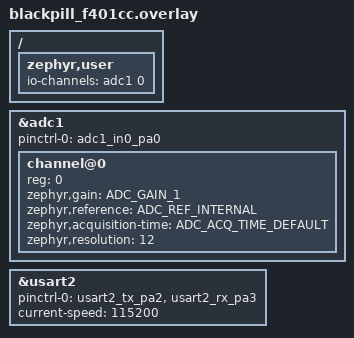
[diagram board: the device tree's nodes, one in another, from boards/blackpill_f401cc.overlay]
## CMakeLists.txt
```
cmake_minimum_required(VERSION 3.20.0)

find_package(Zephyr REQUIRED HINTS $ENV{ZEPHYR_BASE})
project(dut_stm32_integrated)

target_sources(app PRIVATE
    src/main.c
    src/dio_app.c
    src/adc_app.c
    src/uart_app.c

)
```

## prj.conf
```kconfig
CONFIG_GPIO=y
CONFIG_ADC=y
CONFIG_SERIAL=y
CONFIG_UART_CONSOLE=n
CONFIG_PRINTK=y
CONFIG_UART_INTERRUPT_DRIVEN=y
```

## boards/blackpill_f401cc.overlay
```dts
#include <zephyr/dt-bindings/adc/adc.h>

/ {
    zephyr,user {
        io-channels = <&adc1 0>;
    };
};

&adc1 {
    status = "okay";

    pinctrl-0 = <&adc1_in0_pa0>;
    pinctrl-names = "default";

    #address-cells = <1>;
    #size-cells = <0>;

    channel@0 {
        reg = <0>;
        zephyr,gain = "ADC_GAIN_1";
        zephyr,reference = "ADC_REF_INTERNAL";
        zephyr,acquisition-time = <ADC_ACQ_TIME_DEFAULT>;
        zephyr,resolution = <12>;
    };
};

&usart2 {
    pinctrl-0 = <&usart2_tx_pa2 &usart2_rx_pa3>;
    pinctrl-names = "default";
    current-speed = <115200>;
    status = "okay";
};
```

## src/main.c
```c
#include <zephyr/kernel.h>
#include <zephyr/sys/printk.h>

#include "dio_app.h"
#include "adc_app.h"
#include "uart_app.h"

int main(void)
{
    printk("STM32 integrated DUT started\n");

    if (dio_app_init() != 0) {
        printk("ERROR: DIO app init failed\n");
        return 0;
    }

    if (adc_app_init() != 0) {
        printk("ERROR: ADC app init failed\n");
        return 0;
    }

    if (uart_app_init() != 0) {
        printk("ERROR: UART app init failed\n");
        return 0;
    }

    while (1) {
        dio_app_update();
        adc_app_update();
        uart_app_update();

        k_msleep(10);
    }

    return 0;
}
```

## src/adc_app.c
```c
#include "adc_app.h"

#include <zephyr/device.h>
#include <zephyr/drivers/adc.h>
#include <zephyr/drivers/gpio.h>
#include <zephyr/sys/printk.h>

/*
 * ADC DUT behavior:
 *
 * PA0 = ADC_IN / ADC1 channel 0
 * PB5 = WARNING_OUT
 *
 * ADC raw <  1800 -> PB5 LOW
 * ADC raw >= 1800 -> PB5 HIGH
 *
 * Notes:
 * - STM32F401 ADC is 12-bit.
 * - Raw range is approximately:
 *   0    ~= 0V
 *   4095 ~= 3.3V
 * - 1500mV threshold approximately:
 *   1500 / 3300 * 4095 ~= 1860
 */

#define ADC_DT_SPEC ADC_DT_SPEC_GET(DT_PATH(zephyr_user))

#define WARNING_GPIO_NODE DT_NODELABEL(gpiob)
#define WARNING_OUT_PIN   5

#define ADC_RAW_THRESHOLD 1800

static const struct adc_dt_spec adc_channel = ADC_DT_SPEC;
static const struct device *warning_gpio = DEVICE_DT_GET(WARNING_GPIO_NODE);

static int16_t sample_buffer;

static struct adc_sequence sequence = {
    .buffer = &sample_buffer,
    .buffer_size = sizeof(sample_buffer),
};

int adc_app_init(void)
{
    int ret;

    if (!device_is_ready(warning_gpio)) {
        printk("ERROR: WARNING GPIO device is not ready\n");
        return -1;
    }

    ret = gpio_pin_configure(warning_gpio, WARNING_OUT_PIN, GPIO_OUTPUT_INACTIVE);
    if (ret < 0) {
        printk("ERROR: Failed to configure PB5 WARNING_OUT, ret=%d\n", ret);
        return ret;
    }

    if (!adc_is_ready_dt(&adc_channel)) {
        printk("ERROR: ADC device is not ready\n");
        return -1;
    }

    ret = adc_channel_setup_dt(&adc_channel);
    if (ret < 0) {
        printk("ERROR: ADC channel setup failed, ret=%d\n", ret);
        return ret;
    }

    ret = adc_sequence_init_dt(&adc_channel, &sequence);
    if (ret < 0) {
        printk("ERROR: ADC sequence init failed, ret=%d\n", ret);
        return ret;
    }

    printk("ADC app initialized: PA0 ADC_IN -> PB5 WARNING_OUT, raw_threshold=%d\n",
           ADC_RAW_THRESHOLD);

    return 0;
}

void adc_app_update(void)
{
    int ret;

    ret = adc_read_dt(&adc_channel, &sequence);
    if (ret < 0) {
        printk("ERROR: ADC read failed, ret=%d\n", ret);
        return;
    }

    if (sample_buffer >= ADC_RAW_THRESHOLD) {
        gpio_pin_set_raw(warning_gpio, WARNING_OUT_PIN, 1);
    } else {
        gpio_pin_set_raw(warning_gpio, WARNING_OUT_PIN, 0);
    }
}
```

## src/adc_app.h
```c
#ifndef ADC_APP_H
#define ADC_APP_H

int adc_app_init(void);
void adc_app_update(void);

#endif
```

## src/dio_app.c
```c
#include "dio_app.h"

#include <zephyr/device.h>
#include <zephyr/drivers/gpio.h>
#include <zephyr/sys/printk.h>

#define DIO_GPIO_NODE DT_NODELABEL(gpiob)

#define BUTTON_IN_PIN 0
#define LED_OUT_PIN   1

static const struct device *gpio_b = DEVICE_DT_GET(DIO_GPIO_NODE);

int dio_app_init(void)
{
    int ret;

    if (!device_is_ready(gpio_b)) {
        printk("ERROR: GPIOB device is not ready\n");
        return -1;
    }

    ret = gpio_pin_configure(gpio_b, BUTTON_IN_PIN, GPIO_INPUT | GPIO_PULL_DOWN);
    if (ret < 0) {
        printk("ERROR: Failed to configure PB0 BUTTON_IN\n");
        return ret;
    }

    ret = gpio_pin_configure(gpio_b, LED_OUT_PIN, GPIO_OUTPUT_INACTIVE);
    if (ret < 0) {
        printk("ERROR: Failed to configure PB1 LED_OUT\n");
        return ret;
    }

    printk("DIO app initialized: PB0 -> PB1\n");
    return 0;
}

void dio_app_update(void)
{
    int button_state = gpio_pin_get_raw(gpio_b, BUTTON_IN_PIN);

    if (button_state < 0) {
        printk("ERROR: Failed to read PB0\n");
        return;
    }

    gpio_pin_set_raw(gpio_b, LED_OUT_PIN, button_state ? 1 : 0);
}
```

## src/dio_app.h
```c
#ifndef DIO_APP_H
#define DIO_APP_H

int dio_app_init(void);
void dio_app_update(void);

#endif
```

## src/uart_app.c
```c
#include "uart_app.h"

#include <zephyr/device.h>
#include <zephyr/drivers/uart.h>
#include <zephyr/kernel.h>
#include <zephyr/sys/printk.h>

#include <stdbool.h>
#include <string.h>

/*
 * STM32 UART DUT behavior
 *
 * USART2:
 * - PA2 = USART2_TX
 * - PA3 = USART2_RX
 *
 * Behavior:
 * - Receive "PING"  -> Reply "PONG"
 * - Receive "HELLO" -> Reply "ACK"
 * - Otherwise       -> Reply "ERR"
 *
 * RX is interrupt-driven to avoid losing bytes at 115200 baud.
 */

#define DUT_UART_NODE DT_NODELABEL(usart2)

#define RX_BUFFER_SIZE 64

static const struct device *uart_dev = DEVICE_DT_GET(DUT_UART_NODE);

static char rx_buffer[RX_BUFFER_SIZE];
static size_t rx_index;

static char command_buffer[RX_BUFFER_SIZE];
static volatile bool command_ready;

static void uart_send_string(const char *str)
{
    while (*str != '\0') {
        uart_poll_out(uart_dev, *str);
        str++;
    }
}

static void process_command(const char *cmd)
{
    if (strcmp(cmd, "PING") == 0) {
        uart_send_string("PONG\n");
    } else if (strcmp(cmd, "HELLO") == 0) {
        uart_send_string("ACK\n");
    } else {
        uart_send_string("ERR\n");
    }
}

static void uart_rx_callback(const struct device *dev, void *user_data)
{
    (void)user_data;

    if (!uart_irq_update(dev)) {
        return;
    }

    while (uart_irq_rx_ready(dev)) {
        unsigned char c;

        int ret = uart_fifo_read(dev, &c, 1);
        if (ret <= 0) {
            break;
        }

        if (c == '\r' || c == '\n') {
            if (rx_index == 0) {
                continue;
            }

            rx_buffer[rx_index] = '\0';

            if (!command_ready) {
                strncpy(command_buffer, rx_buffer, sizeof(command_buffer) - 1);
                command_buffer[sizeof(command_buffer) - 1] = '\0';
                command_ready = true;
            }

            rx_index = 0;
            continue;
        }

        if (rx_index < RX_BUFFER_SIZE - 1) {
            rx_buffer[rx_index] = (char)c;
            rx_index++;
        } else {
            rx_index = 0;
        }
    }
}

int uart_app_init(void)
{
    int ret;

    if (!device_is_ready(uart_dev)) {
        printk("ERROR: USART2 device is not ready\n");
        return -1;
    }

    rx_index = 0;
    command_ready = false;
    memset(rx_buffer, 0, sizeof(rx_buffer));
    memset(command_buffer, 0, sizeof(command_buffer));

    ret = uart_irq_callback_user_data_set(uart_dev, uart_rx_callback, NULL);
    if (ret < 0) {
        printk("ERROR: Failed to set UART RX callback, ret=%d\n", ret);
        return ret;
    }

    uart_irq_rx_enable(uart_dev);

    printk("UART app initialized: USART2 PA2 TX / PA3 RX\n");

    return 0;
}

void uart_app_update(void)
{
    char local_command[RX_BUFFER_SIZE];

    if (!command_ready) {
        return;
    }

    unsigned int key = irq_lock();

    strncpy(local_command, command_buffer, sizeof(local_command) - 1);
    local_command[sizeof(local_command) - 1] = '\0';

    command_ready = false;
    command_buffer[0] = '\0';

    irq_unlock(key);

    process_command(local_command);
}
```

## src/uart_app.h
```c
#ifndef UART_APP_H
#define UART_APP_H

int uart_app_init(void);
void uart_app_update(void);

#endif
```
